# STM32U599 register map
File version: 0.2
CPU: CM33 r0p1, little endian, MPU, FPU, 4 interrupt priority bits
Registers are 32-bit, read-write, reset 0x0 unless marked. A register's access mark holds for its fields unless they carry their own. Offsets are from the block's base; [hi:lo] are bit positions; {n}, {i} and the like mark numbered series; 'fields as' and 'values as' point back to an identical list.

## DSI
Base 0x40016C00
Same registers: SEC_DSI 0x50016C00
0x00 DSI_VR ro reset 0x3134312A — DSI Host version register
  [31:0] VERSION — Version of the DSI Host This read-only register contains the version of the DSI Host
0x04 DSI_CR — DSI Host control register
  [0] EN — Enable This bit configures the DSI Host in either power-up mode or to reset.
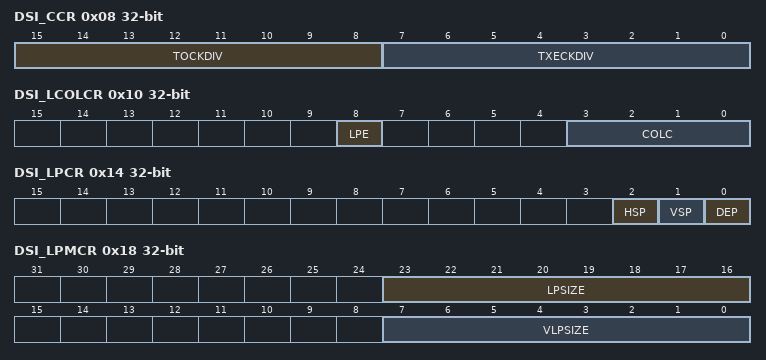
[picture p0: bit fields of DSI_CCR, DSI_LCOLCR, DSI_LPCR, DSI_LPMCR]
0x08 DSI_CCR — DSI Host clock control register
  [15:8] TOCKDIV — Timeout clock division This field indicates the division factor for the timeout clock used as the timing unit in the configuration of HS to LP and LP to HS transition error.
  [7:0] TXECKDIV — TX escape clock division This field indicates the division factor for the TX escape clock source (lanebyteclk). The values 0 and 1 stop the TX_ESC clock generation.
0x0C DSI_LVCIDR — DSI Host LTDC VCID register
  [1:0] VCID — Virtual channel ID These bits configure the virtual channel ID for the LTDC interface traffic.
0x10 DSI_LCOLCR — DSI Host LTDC color coding register
  [8] LPE — Loosely packet enable This bit enables the loosely packed variant to 18-bit configuration
  [3:0] COLC — Color coding This field configures the DPI color coding. Others: Reserved
0x14 DSI_LPCR — DSI Host LTDC polarity configuration register
  [2] HSP — HSYNC polarity This bit configures the polarity of HSYNC pin.
  [1] VSP — VSYNC polarity This bit configures the polarity of VSYNC pin.
  [0] DEP — Data enable polarity This bit configures the polarity of data enable pin.
0x18 DSI_LPMCR — DSI Host low-power mode configuration register
  [23:16] LPSIZE — Largest packet size This field is used for the transmission of commands in low-power mode. It defines the size, in bytes, of the largest packet that can fit in a line during VSA, VBP and VFP regions.
  [7:0] VLPSIZE — VACT largest packet size This field is used for the transmission of commands in low-power mode. It defines the size, in bytes, of the largest packet that can fit in a line during VACT regions.
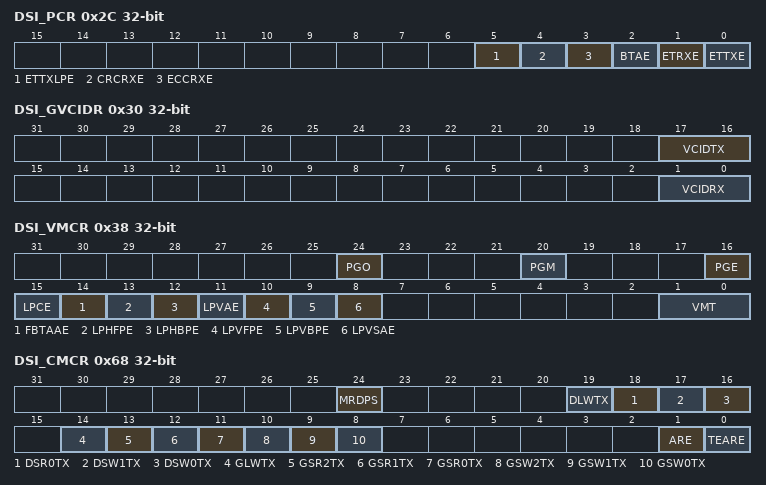
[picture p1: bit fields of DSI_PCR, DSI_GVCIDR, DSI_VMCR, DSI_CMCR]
0x2C DSI_PCR — DSI Host protocol configuration register
  [5] ETTXLPE — EoTp transmission in low-power enable This bit enables the EoTP transmission in low-power.
  [4] CRCRXE — CRC reception enable This bit enables the CRC reception and error reporting.
  [3] ECCRXE — ECC reception enable This bit enables the ECC reception, error correction and reporting.
  [2] BTAE — Bus-turn-around enable This bit enables the bus-turn-around (BTA) request.
  [1] ETRXE — EoTp reception enable This bit enables the EoTp reception.
  [0] ETTXE — EoTp transmission enable This bit enables the EoTP transmission.
0x30 DSI_GVCIDR — DSI Host generic VCID register
  [17:16] VCIDTX — Virtual channel ID for transmission This field indicates the generic interface virtual channel identification where the generic packet is automatically generated and transmitted.
  [1:0] VCIDRX — Virtual channel ID for reception This field indicates the generic interface read-back virtual channel identification.
0x34 DSI_MCR reset 0x1 — DSI Host mode configuration register
  [0] CMDM — Command mode This bit configures the DSI Host in either video or command mode.
0x38 DSI_VMCR — DSI Host video mode configuration register
  [24] PGO — Pattern generator orientation This bit configures the color bar orientation.
  [20] PGM — Pattern generator mode This bit configures the pattern generator mode.
  [16] PGE — Pattern generator enable This bit enables the video mode pattern generator.
  [15] LPCE — Low-power command enable This bit enables the command transmission only in low-power mode.
  [14] FBTAAE — Frame bus-turn-around acknowledge enable This bit enables the request for an acknowledge response at the end of a frame.
  [13] LPHFPE — Low-power horizontal front-porch enable This bit enables the return to low-power inside the horizontal front-porch (HFP) period when timing allows.
  [12] LPHBPE — Low-power horizontal back-porch enable This bit enables the return to low-power inside the horizontal back-porch (HBP) period when timing allows.
  [11] LPVAE — Low-power vertical active enable This bit enables to return to low-power inside the vertical active (VACT) period when timing allows.
  [10] LPVFPE — Low-power vertical front-porch enable This bit enables to return to low-power inside the vertical front-porch (VFP) period when timing allows.
  [9] LPVBPE — Low-power vertical back-porch enable This bit enables to return to low-power inside the vertical back-porch (VBP) period when timing allows.
  [8] LPVSAE — Low-power vertical sync active enable This bit enables to return to low-power inside the vertical sync time (VSA) period when timing allows.
  [1:0] VMT — Video mode type This field configures the video mode transmission type : 1x: Burst mode
0x3C DSI_VPCR — DSI Host video packet configuration register
  [13:0] VPSIZE — Video packet size This field configures the number of pixels in a single video packet. For 18-bit not loosely packed data types, this number must be a multiple of 4. For YCbCr data types, it must be a multiple of 2 as described in the DSI specification.
0x40 DSI_VCCR — DSI Host video chunks configuration register
  [12:0] NUMC — Number of chunks This register configures the number of chunks to be transmitted during a line period (a chunk consists of a video packet and a null packet). If set to 0 or 1, the video line is transmitted in a single packet. If set to 1, the packet is part of a chunk, so a null packet follows it if NPSIZE > 0. Otherwise, multiple chunks are used to transmit each video line.
0x44 DSI_VNPCR — DSI Host video null packet configuration register
  [12:0] NPSIZE — Null packet size This field configures the number of bytes inside a null packet. Setting to 0 disables the null packets.
0x48 DSI_VHSACR — DSI Host video HSA configuration register
  [11:0] HSA — Horizontal synchronism active duration This fields configures the horizontal synchronism active period in lane byte clock cycles.
0x4C DSI_VHBPCR — DSI Host video HBP configuration register
  [11:0] HBP — Horizontal back-porch duration This fields configures the horizontal back-porch period in lane byte clock cycles.
0x50 DSI_VLCR — DSI Host video line configuration register
  [14:0] HLINE — Horizontal line duration This fields configures the total of the horizontal line period (HSA+HBP+HACT+HFP) counted in lane byte clock cycles.
0x54 DSI_VVSACR — DSI Host video VSA configuration register
  [9:0] VSA — Vertical synchronism active duration This fields configures the vertical synchronism active period measured in number of horizontal lines.
0x58 DSI_VVBPCR — DSI Host video VBP configuration register
  [9:0] VBP — Vertical back-porch duration This fields configures the vertical back-porch period measured in number of horizontal lines.
0x5C DSI_VVFPCR — DSI Host video VFP configuration register
  [9:0] VFP — Vertical front-porch duration This fields configures the vertical front-porch period measured in number of horizontal lines.
0x60 DSI_VVACR — DSI Host video VA configuration register
  [13:0] VA — Vertical active duration This fields configures the vertical active period measured in number of horizontal lines.
0x64 DSI_LCCR — DSI Host LTDC command configuration register
  [15:0] CMDSIZE — Command size This field configures the maximum allowed size for an LTDC write memory command, measured in pixels. Automatic partitioning of data obtained from LTDC is permanently enabled.
0x68 DSI_CMCR — DSI Host command mode configuration register
  [24] MRDPS — Maximum read packet size This bit configures the maximum read packet size command transmission type:
  [19] DLWTX — DCS long write transmission This bit configures the DCS long write packet command transmission type:
  [18] DSR0TX — DCS short read zero parameter transmission This bit configures the DCS short read packet with zero parameter command transmission type:
  [17] DSW1TX — DCS short read one parameter transmission This bit configures the DCS short read packet with one parameter command transmission type:
  [16] DSW0TX — DCS short write zero parameter transmission This bit configures the DCS short write packet with zero parameter command transmission type:
  [14] GLWTX — Generic long write transmission This bit configures the generic long write packet command transmission type :
  [13] GSR2TX — Generic short read two parameters transmission This bit configures the generic short read packet with two parameters command transmission type:
  [12] GSR1TX — Generic short read one parameters transmission This bit configures the generic short read packet with one parameters command transmission type:
  [11] GSR0TX — Generic short read zero parameters transmission This bit configures the generic short read packet with zero parameters command transmission type:
  [10] GSW2TX — Generic short write two parameters transmission This bit configures the generic short write packet with two parameters command transmission type:
  [9] GSW1TX — Generic short write one parameters transmission This bit configures the generic short write packet with one parameters command transmission type:
  [8] GSW0TX — Generic short write zero parameters transmission This bit configures the generic short write packet with zero parameters command transmission type:
  [1] ARE — Acknowledge request enable This bit enables the acknowledge request after each packet transmission:
  [0] TEARE — Tearing effect acknowledge request enable This bit enables the tearing effect acknowledge request:
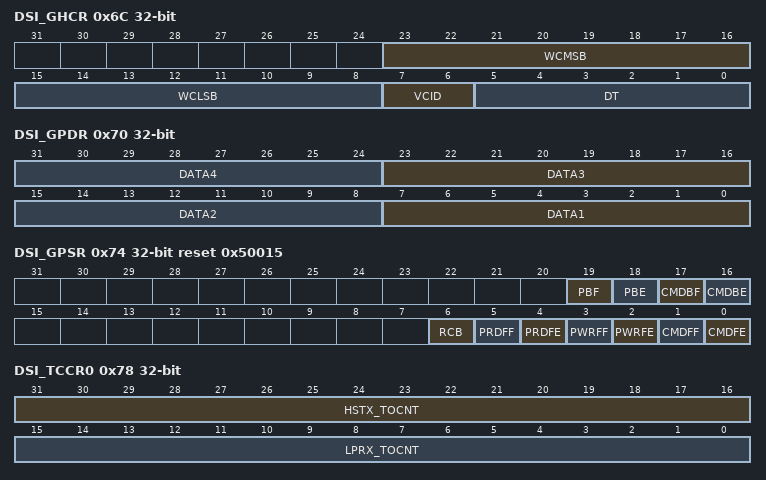
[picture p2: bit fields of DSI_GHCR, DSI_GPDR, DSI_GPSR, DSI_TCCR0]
0x6C DSI_GHCR — DSI Host generic header configuration register
  [23:16] WCMSB — WordCount MSB This field configures the most significant byte of the header packet's word count for long packets, or data 1 for short packets.
  [15:8] WCLSB — WordCount LSB This field configures the less significant byte of the header packet word count for long packets, or data 0 for short packets.
  [7:6] VCID — Channel This field configures the virtual channel ID of the header packet.
  [5:0] DT — Type This field configures the packet data type of the header packet.
0x70 DSI_GPDR — DSI Host generic payload data register
  [8n-1:8n-8] DATA{n} (n=1..4) — Payload byte {n} This field indicates the byte {n} of the packet payload.
0x74 DSI_GPSR ro reset 0x50015 — DSI Host generic packet status register
  [19] PBF — Payload buffer full This bit indicates the full status of the generic payload internal buffer:
  [18] PBE — Payload buffer empty This bit indicates the empty status of the generic payload internal buffer:
  [17] CMDBF — Command buffer full This bit indicates the full status of the generic command internal buffer:
  [16] CMDBE — Command buffer empty This bit indicates the empty status of the generic payload internal buffer:
  [6] RCB — Read command busy This bit is set when a read command is issued and cleared when the entire response is stored in the FIFO:
  [5] PRDFF — Payload read FIFO full This bit indicates the full status of the generic read payload FIFO:
  [4] PRDFE — Payload read FIFO empty This bit indicates the empty status of the generic read payload FIFO:
  [3] PWRFF — Payload write FIFO full This bit indicates the full status of the generic write payload FIFO:
  [2] PWRFE — Payload write FIFO empty This bit indicates the empty status of the generic write payload FIFO:
  [1] CMDFF — Command FIFO full This bit indicates the full status of the generic command FIFO:
  [0] CMDFE — Command FIFO empty This bit indicates the empty status of the generic command FIFO:
0x78 DSI_TCCR0 — DSI Host timeout counter configuration register 0
  [31:16] HSTX_TOCNT — High-speed transmission timeout counter This field configures the timeout counter that triggers a high-speed transmission timeout contention detection (measured in TOCKDIV cycles). If using the non-burst mode and there is no enough time to switch from high-speed to low-power and back in the period from one line data finishing to the next line sync start, the DSI link returns the low-power state once per frame, then configure the TOCKDIV and HSTX_TOCNT to be in accordance with: HSTX_TOCNT * lanebyteclkperiod * TOCKDIV â¥ the time of one FRAME data transmission *Â (1 + 10%) In burst mode, RGB pixel packets are time-compressed, leaving more time during a scan line. Therefore, if in burst mode and there is enough time to switch from high-speed to low-power and back in the period from one line data finishing to the next line sync start, the DSI link can return low-power mode and back in this time interval to save power. For this, configure the TOCKDIV and HSTX_TOCNT to be in accordance with: HSTX_TOCNT * lanebyteclkperiod * TOCKDIV â¥ the time of one LINE data transmission *Â (1Â +Â 10%)
  [15:0] LPRX_TOCNT — Low-power reception timeout counter This field configures the timeout counter that triggers a low-power reception timeout contention detection (measured in TOCKDIV cycles).
0x7C DSI_TCCR1 — DSI Host timeout counter configuration register 1
  [15:0] HSRD_TOCNT — High-speed read timeout counter This field sets a period for which the DSI Host keeps the link still, after sending a high-speed read operation. This period is measured in cycles of lanebyteclk. The counting starts when the D-PHY enters the Stop state and causes no interrupts.
0x80 DSI_TCCR2 — DSI Host timeout counter configuration register 2
  [15:0] LPRD_TOCNT — Low-power read timeout counter This field sets a period for which the DSI Host keeps the link still, after sending a low-power read operation. This period is measured in cycles of lanebyteclk. The counting starts when the D-PHY enters the Stop state and causes no interrupts.
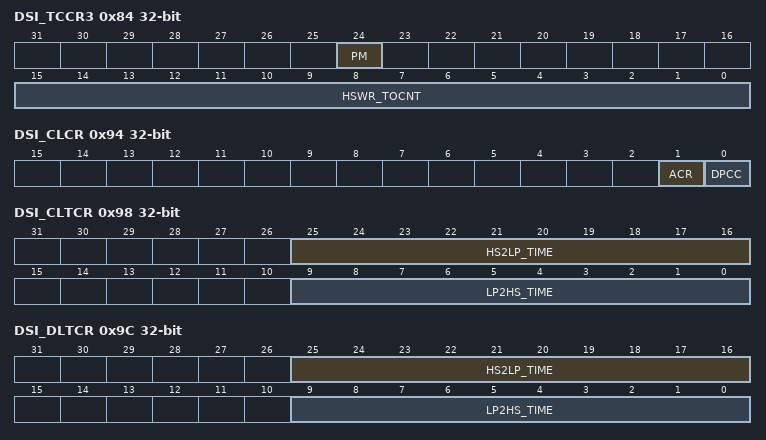
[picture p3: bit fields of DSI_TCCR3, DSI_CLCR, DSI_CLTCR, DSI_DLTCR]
0x84 DSI_TCCR3 — DSI Host timeout counter configuration register 3
  [24] PM — Presp mode When set to 1, this bit ensures that the peripheral response timeout caused by HSWR_TOCNT is used only once per LTDC frame in command mode, when both the following conditions are met: dpivsync_edpiwms has risen and fallen. Packets originated from LTDC in command mode have been transmitted and its FIFO is empty again. In this scenario no non-LTDC command requests are sent to the D-PHY, even if there is traffic from generic interface ready to be sent, making it return to stop state. When it does so, PRESP_TO counter is activated and only when it finishes does the controller send any other traffic that is ready.
  [15:0] HSWR_TOCNT — High-speed write timeout counter This field sets a period for which the DSI Host keeps the link inactive after sending a high-speed write operation. This period is measured in cycles of lanebyteclk. The counting starts when the D-PHY enters the Stop state and causes no interrupts.
0x88 DSI_TCCR4 — DSI Host timeout counter configuration register 4
  [15:0] LPWR_TOCNT — Low-power write timeout counter This field sets a period for which the DSI Host keeps the link still, after sending a low-power write operation. This period is measured in cycles of lanebyteclk. The counting starts when the D-PHY enters the Stop state and causes no interrupts.
0x8C DSI_TCCR5 — DSI Host timeout counter configuration register 5
  [15:0] BTA_TOCNT — Bus-turn-around timeout counter This field sets a period for which the DSI Host keeps the link still, after completing a bus-turn-around. This period is measured in cycles of lanebyteclk. The counting starts when the DâPHY enters the Stop state and causes no interrupts.
0x94 DSI_CLCR — DSI Host clock lane configuration register
  [1] ACR — Automatic clock lane control This bit enables the automatic mechanism to stop providing clock in the clock lane when time allows.
  [0] DPCC — D-PHY clock control This bit controls the D-PHY clock state:
0x98 DSI_CLTCR — DSI Host clock lane timer configuration register
  [25:16] HS2LP_TIME — High-speed to low-power time This field configures the maximum time that the D-PHY clock lane takes to go from highâspeed to low-power transmission measured in lane byte clock cycles.
  [9:0] LP2HS_TIME — Low-power to high-speed time This field configures the maximum time that the D-PHY clock lane takes to go from lowâpower to high-speed transmission measured in lane byte clock cycles.
0x9C DSI_DLTCR — DSI Host data lane timer configuration register
  [25:16] HS2LP_TIME — High-speed to low-power time This field configures the maximum time that the D-PHY data lanes take to go from high-speed to low-power transmission measured in lane byte clock cycles.
  [9:0] LP2HS_TIME — Low-power to high-speed time This field configures the maximum time that the D-PHY data lanes take to go from low-power to high-speed transmission measured in lane byte clock cycles.
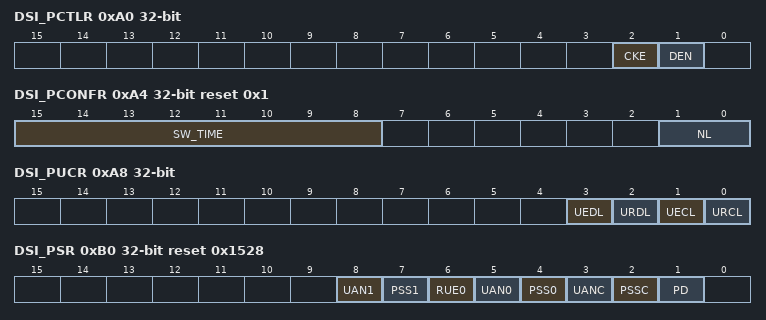
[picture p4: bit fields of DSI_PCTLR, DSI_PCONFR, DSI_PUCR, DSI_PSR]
0xA0 DSI_PCTLR — DSI Host PHY control register
  [2] CKE — Clock enable This bit enables the D-PHY clock lane module:
  [1] DEN — Digital enable When set to 0, this bit places the digital section of the D-PHY in the reset state
0xA4 DSI_PCONFR reset 0x1 — DSI Host PHY configuration register
  [15:8] SW_TIME — Stop wait time This field configures the minimum wait period to request a high-speed transmission after the Stop state.
  [1:0] NL — Number of lanes This field configures the number of active data lanes: Others: Reserved
0xA8 DSI_PUCR — DSI Host PHY ULPS control register
  [3] UEDL — ULPS exit on data lane ULPS mode exit on all active data lanes.
  [2] URDL — ULPS request on data lane ULPS mode request on all active data lanes.
  [1] UECL — ULPS exit on clock lane ULPS mode exit on clock lane.
  [0] URCL — ULPS request on clock lane ULPS mode request on clock lane.
0xAC DSI_PTTCR — DSI Host PHY TX triggers configuration register
  [3:0] TX_TRIG — Transmission trigger Escape mode transmit trigger 0-3. Only one bit of TX_TRIG is asserted at any given time.
0xB0 DSI_PSR ro reset 0x1528 — DSI Host PHY status register
  [8] UAN1 — ULPS active not lane 1 This bit indicates the status of ulpsactivenot1lane D-PHY signal.
  [7] PSS1 — PHY stop state lane 1 This bit indicates the status of phystopstate1lane D-PHY signal.
  [6] RUE0 — RX ULPS escape lane 0 This bit indicates the status of rxulpsesc0lane D-PHY signal.
  [5] UAN0 — ULPS active not lane 1 This bit indicates the status of ulpsactivenot0lane D-PHY signal.
  [4] PSS0 — PHY stop state lane 0 This bit indicates the status of phystopstate0lane D-PHY signal.
  [3] UANC — ULPS active not clock lane This bit indicates the status of ulpsactivenotclklane D-PHY signal.
  [2] PSSC — PHY stop state clock lane This bit indicates the status of phystopstateclklane D-PHY signal.
  [1] PD — PHY direction This bit indicates the status of phydirection D-PHY signal.
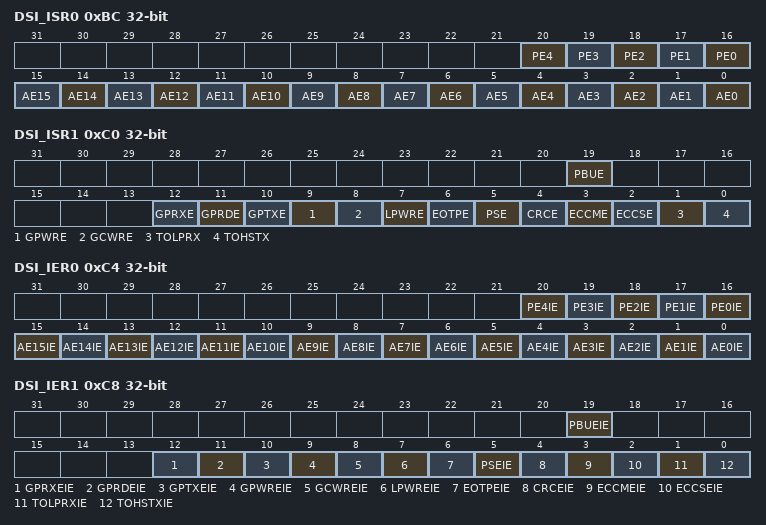
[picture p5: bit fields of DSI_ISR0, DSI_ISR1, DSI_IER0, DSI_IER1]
0xBC DSI_ISR0 ro — DSI Host interrupt and status register 0
  [20] PE4 — PHY error 4 This bit indicates the LP1 contention error ErrContentionLP1 from lane 0.
  [19] PE3 — PHY error 3 This bit indicates the LP0 contention error ErrContentionLP0 from lane 0.
  [18] PE2 — PHY error 2 This bit indicates the ErrControl error from lane 0.
  [17] PE1 — PHY error 1 This bit indicates the ErrSyncEsc low-power transmission synchronization error from lane 0.
  [16] PE0 — PHY error 0 This bit indicates the ErrEsc escape entry error from lane 0.
  [15] AE15 — Acknowledge error 15 This bit retrieves the DSI protocol violation from the acknowledge error report.
  [14] AE14 — Acknowledge error 14 This bit retrieves the reserved (specific to the device) from the acknowledge error report.
  [13] AE13 — Acknowledge error 13 This bit retrieves the invalid transmission length from the acknowledge error report.
  [12] AE12 — Acknowledge error 12 This bit retrieves the DSI VC ID Invalid from the acknowledge error report.
  [11] AE11 — Acknowledge error 11 This bit retrieves the not recognized DSI data type from the acknowledge error report.
  [10] AE10 — Acknowledge error 10 This bit retrieves the checksum error (long packet only) from the acknowledge error report.
  [9] AE9 — Acknowledge error 9 This bit retrieves the ECC error, multi-bit (detected, not corrected) from the acknowledge error report.
  [8] AE8 — Acknowledge error 8 This bit retrieves the ECC error, single-bit (detected and corrected) from the acknowledge error report.
  [7] AE7 — Acknowledge error 7 This bit retrieves the reserved (specific to the device) from the acknowledge error report.
  [6] AE6 — Acknowledge error 6 This bit retrieves the false control error from the acknowledge error report.
  [5] AE5 — Acknowledge error 5 This bit retrieves the peripheral timeout error from the acknowledge error report.
  [4] AE4 — Acknowledge error 4 This bit retrieves the LP transmit sync error from the acknowledge error report.
  [3] AE3 — Acknowledge error 3 This bit retrieves the escape mode entry command error from the acknowledge error report.
  [2] AE2 — Acknowledge error 2 This bit retrieves the EoT sync error from the acknowledge error report.
  [1] AE1 — Acknowledge error 1 This bit retrieves the SoT sync error from the acknowledge error report.
  [0] AE0 — Acknowledge error 0 This bit retrieves the SoT error from the acknowledge error report.
0xC0 DSI_ISR1 ro — DSI Host interrupt and status register 1
  [19] PBUE — Payload buffer underflow error This bit indicates that underflow has occurred when reading payload to build DSI packet for video mode.
  [12] GPRXE — Generic payload receive error This bit indicates that during a generic interface packet read back, the payload FIFO becomes full and the received data is corrupted.
  [11] GPRDE — Generic payload read error This bit indicates that during a DCS read data, the payload FIFO becomes empty and the data sent to the interface is corrupted.
  [10] GPTXE — Generic payload transmit error This bit indicates that during a generic interface packet build, the payload FIFO becomes empty and corrupt data is sent.
  [9] GPWRE — Generic payload write error This bit indicates that the system tried to write a payload data through the generic interface and the FIFO is full. Therefore, the payload is not written.
  [8] GCWRE — Generic command write error This bit indicates that the system tried to write a command through the generic interface and the FIFO is full. Therefore, the command is not written.
  [7] LPWRE — LTDC payload write error This bit indicates that during a DPI pixel line storage, the payload FIFO becomes full and the data stored is corrupted.
  [6] EOTPE — EoTp error This bit indicates that the EoTp packet is not received at the end of the incoming peripheral transmission.
  [5] PSE — Packet size error This bit indicates that the packet size error is detected during the packet reception.
  [4] CRCE — CRC error This bit indicates that the CRC error is detected in the received packet payload.
  [3] ECCME — ECC multi-bit error This bit indicates that the ECC multiple error is detected in a received packet.
  [2] ECCSE — ECC single-bit error This bit indicates that the ECC single error is detected and corrected in a received packet.
  [1] TOLPRX — Timeout low-power reception This bit indicates that the low-power reception timeout counter reached the end and contention is detected.
  [0] TOHSTX — Timeout high-speed transmission This bit indicates that the high-speed transmission timeout counter reached the end and contention is detected.
0xC4 DSI_IER0 — DSI Host interrupt enable register 0
  [20] PE4IE — PHY error 4 interrupt enable This bit enables the interrupt generation on PHY error 4.
  [19] PE3IE — PHY error 3 interrupt enable This bit enables the interrupt generation on PHY error 4.
  [18] PE2IE — PHY error 2 interrupt enable This bit enables the interrupt generation on PHY error 2.
  [17] PE1IE — PHY error 1 interrupt enable This bit enables the interrupt generation on PHY error 1.
  [16] PE0IE — PHY error 0 interrupt enable This bit enables the interrupt generation on PHY error 0.
  [n] AE{n}IE (n=0..15) — Acknowledge error {n} interrupt enable This bit enables the interrupt generation on acknowledge error {n}.
0xC8 DSI_IER1 — DSI Host interrupt enable register 1
  [19] PBUEIE — Payload buffer underflow error interrupt enable This bit enables the interrupt generation on payload buffer underflow error.
  [12] GPRXEIE — Generic payload receive error interrupt enable This bit enables the interrupt generation on generic payload receive error.
  [11] GPRDEIE — Generic payload read error interrupt enable This bit enables the interrupt generation on generic payload read error.
  [10] GPTXEIE — Generic payload transmit error interrupt enable This bit enables the interrupt generation on generic payload transmit error.
  [9] GPWREIE — Generic payload write error interrupt enable This bit enables the interrupt generation on generic payload write error.
  [8] GCWREIE — Generic command write error interrupt enable This bit enables the interrupt generation on generic command write error.
  [7] LPWREIE — LTDC payload write error interrupt enable This bit enables the interrupt generation on LTDC payload write error.
  [6] EOTPEIE — EoTp error interrupt enable This bit enables the interrupt generation on EoTp error.
  [5] PSEIE — Packet size error interrupt enable This bit enables the interrupt generation on packet size error.
  [4] CRCEIE — CRC error interrupt enable This bit enables the interrupt generation on CRC error.
  [3] ECCMEIE — ECC multi-bit error interrupt enable This bit enables the interrupt generation on ECC multi-bit error.
  [2] ECCSEIE — ECC single-bit error interrupt enable This bit enables the interrupt generation on ECC single-bit error.
  [1] TOLPRXIE — Timeout low-power reception interrupt enable This bit enables the interrupt generation on timeout low-power reception.
  [0] TOHSTXIE — Timeout high-speed transmission interrupt enable This bit enables the interrupt generation on timeout high-speed transmission .
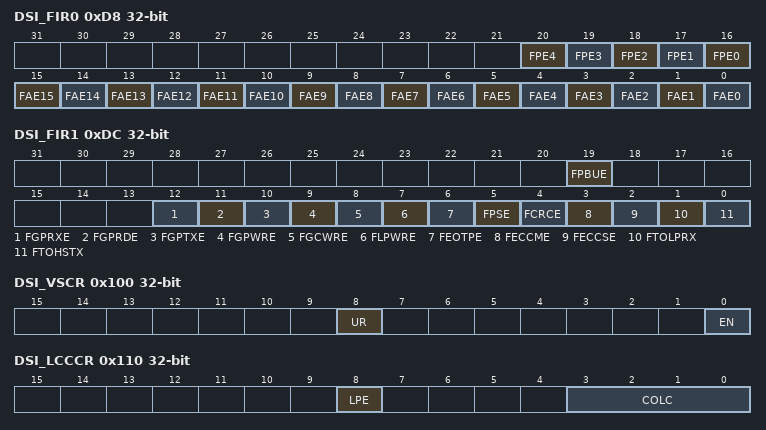
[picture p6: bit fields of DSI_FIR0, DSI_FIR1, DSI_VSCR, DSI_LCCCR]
0xD8 DSI_FIR0 wo — DSI Host force interrupt register 0
  [n+16] FPE{n} (n=0..4) — Force PHY error {n} Writing one to this bit forces a PHY error {n}.
  [n] FAE{n} (n=0..15) — Force acknowledge error {n} Writing one to this bit forces an acknowledge error {n}.
0xDC DSI_FIR1 wo — DSI Host force interrupt register 1
  [19] FPBUE — Force payload buffer underflow error Writing one to this bit forces a payload undrflow error.
  [12] FGPRXE — Force generic payload receive error Writing one to this bit forces a generic payload receive error.
  [11] FGPRDE — Force generic payload read error Writing one to this bit forces a generic payload read error.
  [10] FGPTXE — Force generic payload transmit error Writing one to this bit forces a generic payload transmit error.
  [9] FGPWRE — Force generic payload write error Writing one to this bit forces a generic payload write error.
  [8] FGCWRE — Force generic command write error Writing one to this bit forces a generic command write error.
  [7] FLPWRE — Force LTDC payload write error Writing one to this bit forces a LTDC payload write error.
  [6] FEOTPE — Force EoTp error Writing one to this bit forces a EoTp error.
  [5] FPSE — Force packet size error Writing one to this bit forces a packet size error.
  [4] FCRCE — Force CRC error Writing one to this bit forces a CRC error.
  [3] FECCME — Force ECC multi-bit error Writing one to this bit forces a ECC multi-bit error.
  [2] FECCSE — Force ECC single-bit error Writing one to this bit forces a ECC single-bit error.
  [1] FTOLPRX — Force timeout low-power reception Writing one to this bit forces a timeout low-power reception.
  [0] FTOHSTX — Force timeout high-speed transmission Writing one to this bit forces a timeout high-speed transmission.
0xF4 DSI_DLTRCR — DSI Host data lane timer read configuration register
  [14:0] MRD_TIME — Maximum read time This field configures the maximum time required to perform a read command in lane byte clock cycles. This register can only be modified when no read command is in progress.
0x100 DSI_VSCR — DSI Host video shadow control register
  [8] UR — Update register When set to 1, the LTDC registers are copied to the auxiliary registers. After copying, this bit is auto cleared.
  [0] EN — Enable When set to 1, DSI Host LTDC interface receives the active configuration from the auxiliary registers. When this bit is set along with the UR bit, the auxiliary registers are automatically updated.
0x10C DSI_LCVCIDR — DSI Host LTDC current VCID register
  [1:0] VCID — Virtual channel ID This field returns the virtual channel ID for the LTDC interface.
0x110 DSI_LCCCR ro — DSI Host LTDC current color coding register
  [8] LPE — Loosely packed enable This bit returns the current state of the loosely packed variant to 18-bit configurations.
  [3:0] COLC — Color coding This field returns the current LTDC interface color coding. 0110-1111: reserved If LTDC interface in command mode is chosen and currently works in the command mode (CMDM=1), then 0110-1111: 24-bit
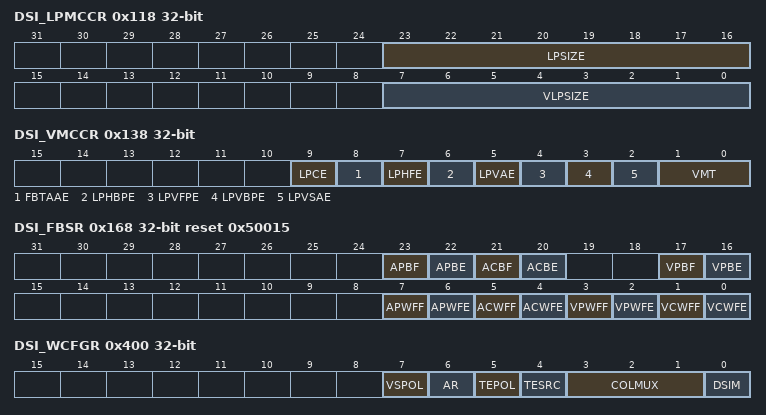
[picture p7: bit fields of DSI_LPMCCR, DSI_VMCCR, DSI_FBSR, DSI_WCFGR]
0x118 DSI_LPMCCR ro — DSI Host low-power mode current configuration register
  [23:16] LPSIZE — Largest packet size This field is returns the current size, in bytes, of the largest packet that can fit in a line during VSA, VBP and VFP regions, for the transmission of commands in low-power mode.
  [7:0] VLPSIZE — VACT largest packet size This field returns the current size, in bytes, of the largest packet that can fit in a line during VACT regions, for the transmission of commands in low-power mode.
0x138 DSI_VMCCR ro — DSI Host video mode current configuration register
  [9] LPCE — Low-power command enable This bit returns the current command transmission state in low-power mode.
  [8] FBTAAE — Frame BTA acknowledge enable This bit returns the current state of request for an acknowledge response at the end of a frame.
  [7] LPHFE — Low-power horizontal front-porch enable This bit returns the current state of return to low-power inside the horizontal front-porch (HFP) period when timing allows.
  [6] LPHBPE — Low-power horizontal back-porch enable This bit returns the current state of return to low-power inside the horizontal back-porch (HBP) period when timing allows.
  [5] LPVAE — Low-power vertical active enable This bit returns the current state of return to low-power inside the vertical active (VACT) period when timing allows.
  [4] LPVFPE — Low-power vertical front-porch enable This bit returns the current state of return to low-power inside the vertical front-porch (VFP) period when timing allows.
  [3] LPVBPE — Low-power vertical back-porch enable This bit returns the current state of return to low-power inside the vertical back-porch (VBP) period when timing allows.
  [2] LPVSAE — Low-power vertical sync time enable This bit returns the current state of return to low-power inside the vertical sync time (VSA) period when timing allows.
  [1:0] VMT — Video mode type This field returns the current video mode transmission type: 1x: Burst mode
0x13C DSI_VPCCR ro — DSI Host video packet current configuration register
  [13:0] VPSIZE — Video packet size This field returns the number of pixels in a single video packet.
0x140 DSI_VCCCR ro — DSI Host video chunks current configuration register
  [12:0] NUMC — Number of chunks This field returns the number of chunks being transmitted during a line period.
0x144 DSI_VNPCCR ro — DSI Host video null packet current configuration register
  [12:0] NPSIZE — Null packet size This field returns the number of bytes inside a null packet.
0x148 DSI_VHSACCR ro — DSI Host video HSA current configuration register
  [11:0] HSA — Horizontal synchronism active duration This fields returns the horizontal synchronism active period in lane byte clock cycles.
0x14C DSI_VHBPCCR ro — DSI Host video HBP current configuration register
  [11:0] HBP — Horizontal back-porch duration This field returns the horizontal back-porch period in lane byte clock cycles.
0x150 DSI_VLCCR ro — DSI Host video line current configuration register
  [14:0] HLINE — Horizontal line duration This field returns the current total of the horizontal line period (HSA+HBP+HACT+HFP) counted in lane byte clock cycles.
0x154 DSI_VVSACCR ro — DSI Host video VSA current configuration register
  [9:0] VSA — Vertical synchronism active duration This field returns the current vertical synchronism active period measured in number of horizontal lines.
0x158 DSI_VVBPCCR ro — DSI Host video VBP current configuration register
  [9:0] VBP — Vertical back-porch duration This field returns the current vertical back-porch period measured in number of horizontal lines.
0x15C DSI_VVFPCCR ro — DSI Host video VFP current configuration register
  [9:0] VFP — Vertical front-porch duration This field returns the current vertical front-porch period measured in number of horizontal lines.
0x160 DSI_VVACCR ro — DSI Host video VA current configuration register
  [13:0] VA — Vertical active duration This field returns the current vertical active period measured in number of horizontal lines.
0x168 DSI_FBSR ro reset 0x50015 — DSI Host FIFO and buffer status register
  [23] APBF — Adapted command mode payload buffer full This bit indicates the full status of the adapted command mode payload internal buffer:
  [22] APBE — Adapted command mode payload buffer empty This bit indicates the empty status of the adapted command mode payload internal buffer:
  [21] ACBF — Adapted command mode command buffer full This bit indicates the full status of the adapted command mode command internal buffer:
  [20] ACBE — Adapted command mode command buffer empty This bit indicates the empty status of the adapted command mode command internal buffer:
  [17] VPBF — Video mode payload buffer full This bit indicates the full status of the video mode payload internal buffer:
  [16] VPBE — Video mode payload buffer empty This bit indicates the empty status of the video mode payload internal buffer:
  [7] APWFF — Adapted command mode payload write FIFO full This bit indicates the full status of the adapted command mode write payload FIFO:
  [6] APWFE — Adapted command mode payload write FIFO empty This bit indicates the empty status of the adapted command mode write payload FIFO:
  [5] ACWFF — Adapted command mode command write FIFO full This bit indicates the full status of the adapted command mode write command FIFO:
  [4] ACWFE — Adapted command mode command write FIFO empty This bit indicates the empty status of the adapted command mode write command FIFO:
  [3] VPWFF — Video mode payload write FIFO full This bit indicates the full status of the video mode write payload FIFO:
  [2] VPWFE — Video mode payload write FIFO empty This bit indicates the empty status of the video mode write payload FIFO:
  [1] VCWFF — Video mode command write FIFO full This bit indicates the full status of the video mode write command FIFO:
  [0] VCWFE — Video mode command write FIFO empty This bit indicates the empty status of the video mode write command FIFO:
0x400 DSI_WCFGR — DSI Wrapper configuration register
  [7] VSPOL — VSync polarity This bit selects the VSync edge on which the LTDC is halted. This bit must only be changed when DSI is stopped (DSI_WCR.DSIEN = 0 and DSI_CR.ENÂ =Â 0).
  [6] AR — Automatic refresh This bit selects the refresh mode in DBI mode. This bit must only be changed when DSI Host is stopped (DSI_CR.EN = 0).
  [5] TEPOL — TE polarity This bit selects the polarity of the external pin tearing effect (TE) source. This bit must only be changed when DSI Host is stopped (DSI_CR.EN = 0).
  [4] TESRC — TE source This bit selects the tearing effect (TE) source. This bit must only be changed when DSI Host is stopped (DSI_CR.EN = 0).
  [3:1] COLMUX — Color multiplexing This bit selects the color multiplexing used by DSI Host. This field must only be changed when DSI is stopped (DSI_WCR.DSIEN = 0 and DSI_CR.ENÂ =Â 0).
  [0] DSIM — DSI mode This bit selects the mode for the video transmission. This bit must only be changed when DSI Host is stopped (DSI_CR.EN = 0).
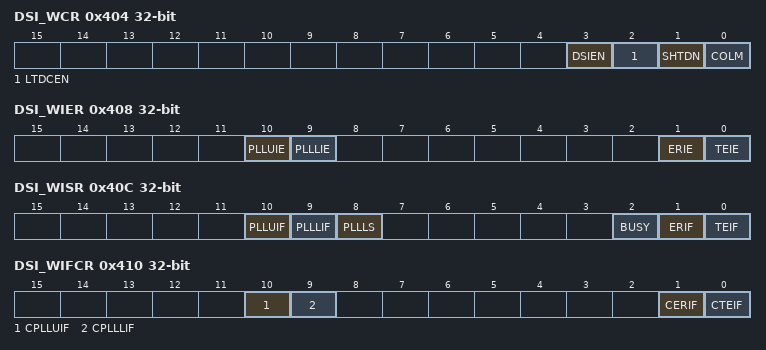
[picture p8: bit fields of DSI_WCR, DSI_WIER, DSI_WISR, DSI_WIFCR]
0x404 DSI_WCR — DSI Wrapper control register
  [3] DSIEN — DSI enable This bit enables the DSI Wrapper.
  [2] LTDCEN — LTDC enable This bit enables the LTDC for a frame transfer in adapted command mode.
  [1] SHTDN — Shutdown This bit controls the display shutdown in video mode.
  [0] COLM — Color mode This bit controls the display color mode in video mode.
0x408 DSI_WIER — DSI Wrapper interrupt enable register
  [10] PLLUIE — PLL unlock interrupt enable This bit enables the PLL unlock interrupt.
  [9] PLLLIE — PLL lock interrupt enable This bit enables the PLL lock interrupt.
  [1] ERIE — End of refresh interrupt enable This bit enables the end of refresh interrupt.
  [0] TEIE — Tearing effect interrupt enable This bit enables the tearing effect interrupt.
0x40C DSI_WISR ro — DSI Wrapper interrupt and status register
  [10] PLLUIF — PLL unlock interrupt flag This bit is set when the PLL becomes unlocked.
  [9] PLLLIF — PLL lock interrupt flag This bit is set when the PLL becomes locked.
  [8] PLLLS — PLL lock status This bit is set when the PLL is locked and cleared when it is unlocked.
  [2] BUSY — Busy flag This bit is set when the transfer of a frame in adapted command mode is ongoing.
  [1] ERIF — End of refresh interrupt flag This bit is set when the transfer of a frame in adapted command mode is finished.
  [0] TEIF — Tearing effect interrupt flag This bit is set when a tearing effect event occurs.
0x410 DSI_WIFCR wo — DSI Wrapper interrupt flag clear register
  [10] CPLLUIF — Clear PLL unlock interrupt flag Write 1 clears the PLLUIF flag in the DSI_WSR register.
  [9] CPLLLIF — Clear PLL lock interrupt flag Write 1 clears the PLLLIF flag in the DSI_WSR register.
  [1] CERIF — Clear end of refresh interrupt flag Write 1 clears the ERIF flag in the DSI_WSR register.
  [0] CTEIF — Clear tearing effect interrupt flag Write 1 clears the TEIF flag in the DSI_WSR register.
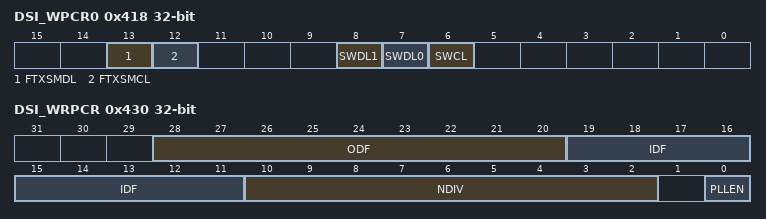
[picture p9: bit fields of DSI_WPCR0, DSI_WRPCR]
0x418 DSI_WPCR0 — DSI Wrapper PHY configuration register 0
  [13] FTXSMDL — Force in TX Stop mode the data lanes This bit forces the data lanes in TX stop mode. It is used to initialize a lane module in transmit mode. It causes the lane module to immediately jump to transmit control mode and to begin transmitting a stop state (LP-11). It can be used to go back in TX mode after a wrong BTA sequence.
  [12] FTXSMCL — Force in TX Stop mode the clock lane This bit forces the clock lane in TX stop mode. It is used to initialize a lane module in transmit mode. It causes the lane module to immediately jump to transmit control mode and to begin transmitting a stop state (LP-11). It can be used to go back in TX mode after a wrong BTA sequence.
  [8] SWDL1 — Swap data lane 1 pins This bit swaps the pins on clock lane.
  [7] SWDL0 — Swap data lane 0 pins This bit swaps the pins on data lane 0.
  [6] SWCL — Swap clock lane pins This bit swaps the pins on clock lane.
0x430 DSI_WRPCR — DSI Wrapper regulator and PLL control register
  [28:20] ODF — PLL output division factor This field configures the PLL output division factor. 2: PLL output divided by 2 ... 511: PLL output divided by 511
  [19:11] IDF — PLL input division factor This field configures the PLL input division factor. 2: PLL input divided by 2 ... 511: PLL input divided by 511
  [10:2] NDIV — PLL loop division factor This field configures the PLL loop division factor. 2: PLL loop divided by 2x2 ... 511: PLL loop divided by 511x2
  [0] PLLEN — PLL enable This bit enables the D-PHY PLL.
0x808 DSI_BCFGR — DSI bias configuration register
  [6] PWRUP — Power-up This bit powers-up the reference bias for the MIPI D-PHY
0xC04 DSI_DPCBCR — DSI D-PHY clock band control register
  [7:3] BC — Band control This field selects the frequency band used by the D-PHY. Others: Reserved
0xC34 DSI_DPCSRCR — DSI D-PHY clock skew rate control register
  [7:0] SRC — Slew rate control This field selects the slew rate for HS-TX speed. Others: Reserved
0xC70 DSI_DPDL0BCR — DSI D-PHY data lane 0 band control register
  [4:0] BC — Band control This field selects the frequency band used by the D-PHY. Others: Reserved
0xCA0 DSI_DPDL0SRCR — DSI D-PHY data lane 0 skew rate control register
  fields as DSI_DPCSRCR
0xD08 DSI_DPDL1BCR — DSI D-PHY data lane 1 band control register
  fields as DSI_DPDL0BCR
0xD38 DSI_DPDL1SRCR — DSI D-PHY data lane 1 skew rate control register
  fields as DSI_DPCSRCR
